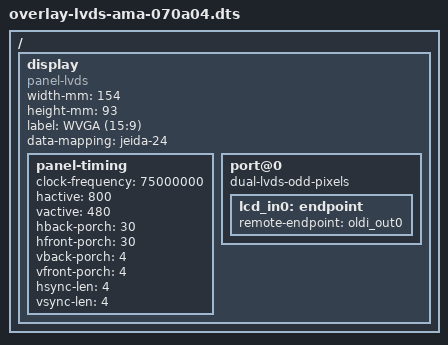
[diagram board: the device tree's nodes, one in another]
/*
 * Copyright (C) 2022 Avnet Embedded GmbH
 *
 * This program is free software; you can redistribute it and/or
 * modify it under the terms of the GNU General Public License as
 * published by the Free Software Foundation version 2.
 *
 * This program is distributed "as is" WITHOUT ANY WARRANTY of any
 * kind, whether express or implied; without even the implied warranty
 * of MERCHANTABILITY or FITNESS FOR A PARTICULAR PURPOSE.  See the
 * GNU General Public License for more details.
 */

/dts-v1/;
/plugin/;


/ {
       fragment@4000 {
               target-path = "/";
               __overlay__ {
                       display {
                               compatible = "panel-lvds";
                		width-mm = <154>;
                		height-mm = <93>;
                		label = "WVGA (15:9)";
                		data-mapping = "jeida-24";
                		status = "okay";

                		panel-timing {
                		        clock-frequency = <75000000>;
                		        hactive = <800>;
                		        vactive = <480>;
                		        hback-porch = <30>;
                		        hfront-porch = <30>;
                		        vback-porch = <4>;
                		        vfront-porch = <4>;
                		        hsync-len = <4>;
                		        vsync-len = <4>;
                		};

                		port@0 {
                		    dual-lvds-odd-pixels;
                		    lcd_in0: endpoint {
                		            remote-endpoint = <&oldi_out0>;
                		    };
                		};
                       };
               };
       };
};

